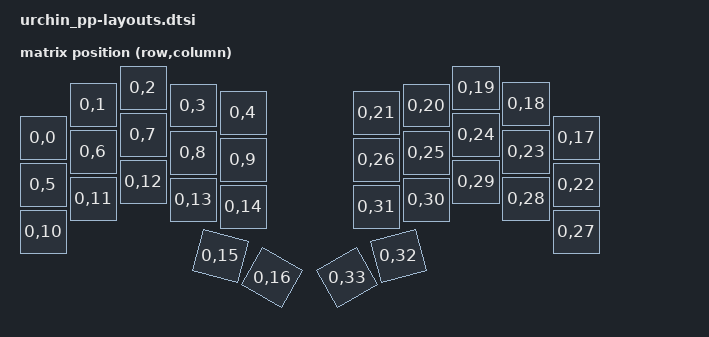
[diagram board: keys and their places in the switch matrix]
/* Generated by scripts/firmware/gen_board.py from hardware/pinmap.json and hardware/geometry/urchin.json. Do not edit. */

#include <physical_layouts.dtsi>

/ {
    default_transform: keymap_transform_0 {
        compatible = "zmk,matrix-transform";
        rows = <1>;
        columns = <34>;
        map = <
            RC(0,0) RC(0,1) RC(0,2) RC(0,3) RC(0,4) RC(0,21) RC(0,20) RC(0,19) RC(0,18) RC(0,17)
            RC(0,5) RC(0,6) RC(0,7) RC(0,8) RC(0,9) RC(0,26) RC(0,25) RC(0,24) RC(0,23) RC(0,22)
            RC(0,10) RC(0,11) RC(0,12) RC(0,13) RC(0,14) RC(0,31) RC(0,30) RC(0,29) RC(0,28) RC(0,27)
            RC(0,15) RC(0,16) RC(0,33) RC(0,32)
        >;
    };

    physical_layout0: physical_layout_0 {
        compatible = "zmk,physical-layout";
        display-name = "urchin++";
        transform = <&default_transform>;
        keys  //                     w   h     x    y      rot    rx    ry
            = <&key_physical_attrs 100  94     0  100        0    50   147>  /* 0: left r0c0 SW1 */
            , <&key_physical_attrs 100  94   100   34        0   150    81>  /* 1: left r0c1 SW2 */
            , <&key_physical_attrs 100  94   200    0        0   250    47>  /* 2: left r0c2 SW3 */
            , <&key_physical_attrs 100  94   300   36        0   350    83>  /* 3: left r0c3 SW4 */
            , <&key_physical_attrs 100  94   400   50        0   450    97>  /* 4: left r0c4 SW5 */
            , <&key_physical_attrs 100  94   666   50        0   716    97>  /* 5: right r0c4 SW18 */
            , <&key_physical_attrs 100  94   766   36        0   816    83>  /* 6: right r0c3 SW19 */
            , <&key_physical_attrs 100  94   866    0        0   916    47>  /* 7: right r0c2 SW20 */
            , <&key_physical_attrs 100  94   966   33        0  1016    80>  /* 8: right r0c1 SW21 */
            , <&key_physical_attrs 100  94  1066  100        0  1116   147>  /* 9: right r0c0 SW22 */
            , <&key_physical_attrs 100  94     0  195        0    50   242>  /* 10: left r1c0 SW6 */
            , <&key_physical_attrs 100  94   100  128        0   150   175>  /* 11: left r1c1 SW7 */
            , <&key_physical_attrs 100  94   200   95        0   250   142>  /* 12: left r1c2 SW8 */
            , <&key_physical_attrs 100  94   300  131        0   350   178>  /* 13: left r1c3 SW9 */
            , <&key_physical_attrs 100  94   400  145        0   450   192>  /* 14: left r1c4 SW10 */
            , <&key_physical_attrs 100  94   666  144        0   716   191>  /* 15: right r1c4 SW23 */
            , <&key_physical_attrs 100  94   766  131        0   816   178>  /* 16: right r1c3 SW24 */
            , <&key_physical_attrs 100  94   866   94        0   916   141>  /* 17: right r1c2 SW25 */
            , <&key_physical_attrs 100  94   966  128        0  1016   175>  /* 18: right r1c1 SW26 */
            , <&key_physical_attrs 100  94  1066  194        0  1116   241>  /* 19: right r1c0 SW27 */
            , <&key_physical_attrs 100  94     0  289        0    50   336>  /* 20: left r2c0 SW11 */
            , <&key_physical_attrs 100  94   100  222        0   150   269>  /* 21: left r2c1 SW12 */
            , <&key_physical_attrs 100  94   200  189        0   250   236>  /* 22: left r2c2 SW13 */
            , <&key_physical_attrs 100  94   300  225        0   350   272>  /* 23: left r2c3 SW14 */
            , <&key_physical_attrs 100  94   400  239        0   450   286>  /* 24: left r2c4 SW15 */
            , <&key_physical_attrs 100  94   666  239        0   716   286>  /* 25: right r2c4 SW28 */
            , <&key_physical_attrs 100  94   766  225        0   816   272>  /* 26: right r2c3 SW29 */
            , <&key_physical_attrs 100  94   866  189        0   916   236>  /* 27: right r2c2 SW30 */
            , <&key_physical_attrs 100  94   966  222        0  1016   269>  /* 28: right r2c1 SW31 */
            , <&key_physical_attrs 100  94  1066  289        0  1116   336>  /* 29: right r2c0 SW32 */
            , <&key_physical_attrs 100  94   355  337     1500   405   384>  /* 30: left t0 SW16 */
            , <&key_physical_attrs 100  94   458  380     3000   508   427>  /* 31: left t1 SW17 */
            , <&key_physical_attrs 100  94   608  380  (-3000)   658   427>  /* 32: right t1 SW33 */
            , <&key_physical_attrs 100  94   711  337  (-1500)   761   384>  /* 33: right t0 SW34 */
            ;
    };
};
